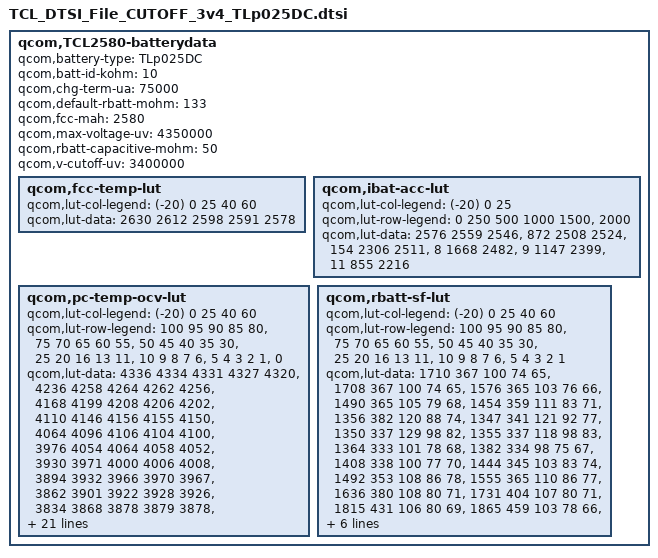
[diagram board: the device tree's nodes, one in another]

qcom,TCL2580-batterydata {
	qcom,battery-type = "TLp025DC";
	qcom,batt-id-kohm = <10>;
	qcom,chg-term-ua = <75000>;
	qcom,default-rbatt-mohm = <133>;
	qcom,fcc-mah = <2580>;
	qcom,max-voltage-uv = <4350000>;
	qcom,rbatt-capacitive-mohm = <50>;
	qcom,v-cutoff-uv = <3400000>;

	qcom,fcc-temp-lut {
		qcom,lut-col-legend = <(-20) 0 25 40 60>;
		qcom,lut-data = <2630 2612 2598 2591 2578>;
	};

	qcom,ibat-acc-lut {
		qcom,lut-col-legend = <(-20) 0 25>;
		qcom,lut-row-legend = <0 250 500 1000 1500>,
					<2000>;
		qcom,lut-data = <2576 2559 2546>,
				<872 2508 2524>,
				<154 2306 2511>,
				<8 1668 2482>,
				<9 1147 2399>,
				<11 855 2216>;
	};

	qcom,pc-temp-ocv-lut {
		qcom,lut-col-legend = <(-20) 0 25 40 60>;
		qcom,lut-row-legend = <100 95 90 85 80>,
					<75 70 65 60 55>,
					<50 45 40 35 30>,
					<25 20 16 13 11>,
					<10 9 8 7 6>,
					<5 4 3 2 1>,
					<0>;
		qcom,lut-data = <4336 4334 4331 4327 4320>,
				<4236 4258 4264 4262 4256>,
				<4168 4199 4208 4206 4202>,
				<4110 4146 4156 4155 4150>,
				<4064 4096 4106 4104 4100>,
				<3976 4054 4064 4058 4052>,
				<3930 3971 4000 4006 4008>,
				<3894 3932 3966 3970 3967>,
				<3862 3901 3922 3928 3926>,
				<3834 3868 3878 3879 3878>,
				<3813 3838 3848 3848 3847>,
				<3795 3814 3824 3824 3824>,
				<3780 3794 3804 3804 3804>,
				<3766 3778 3787 3788 3786>,
				<3751 3766 3771 3770 3766>,
				<3733 3752 3756 3749 3738>,
				<3713 3737 3738 3730 3717>,
				<3692 3722 3717 3708 3695>,
				<3674 3712 3698 3688 3675>,
				<3660 3702 3691 3682 3671>,
				<3651 3698 3689 3681 3670>,
				<3640 3692 3688 3680 3669>,
				<3628 3687 3686 3679 3667>,
				<3612 3680 3683 3675 3662>,
				<3592 3668 3674 3664 3648>,
				<3564 3640 3648 3636 3616>,
				<3528 3598 3602 3590 3568>,
				<3472 3536 3541 3528 3508>,
				<3381 3446 3457 3446 3426>,
				<3226 3304 3334 3318 3294>,
				<3000 3000 3000 3000 3000>;
	};

	qcom,rbatt-sf-lut {
		qcom,lut-col-legend = <(-20) 0 25 40 60>;
		qcom,lut-row-legend = <100 95 90 85 80>,
					<75 70 65 60 55>,
					<50 45 40 35 30>,
					<25 20 16 13 11>,
					<10 9 8 7 6>,
					<5 4 3 2 1>;
		qcom,lut-data = <1710 367 100 74 65>,
				<1708 367 100 74 65>,
				<1576 365 103 76 66>,
				<1490 365 105 79 68>,
				<1454 359 111 83 71>,
				<1356 382 120 88 74>,
				<1347 341 121 92 77>,
				<1350 337 129 98 82>,
				<1355 337 118 98 83>,
				<1364 333 101 78 68>,
				<1382 334 98 75 67>,
				<1408 338 100 77 70>,
				<1444 345 103 83 74>,
				<1492 353 108 86 78>,
				<1555 365 110 86 77>,
				<1636 380 108 80 71>,
				<1731 404 107 80 71>,
				<1815 431 106 80 69>,
				<1865 459 103 78 66>,
				<1811 455 102 77 68>,
				<1868 468 104 80 71>,
				<1956 483 108 83 74>,
				<2094 502 114 87 77>,
				<2269 522 120 91 80>,
				<2496 541 123 90 77>,
				<2811 556 117 84 72>,
				<3235 581 114 83 72>,
				<3932 623 120 87 76>,
				<5799 690 131 96 86>,
				<11598 1380 192 166 129>;
	};
};
/* TEST_DB_ID=TEST_ID_NOT_SET */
